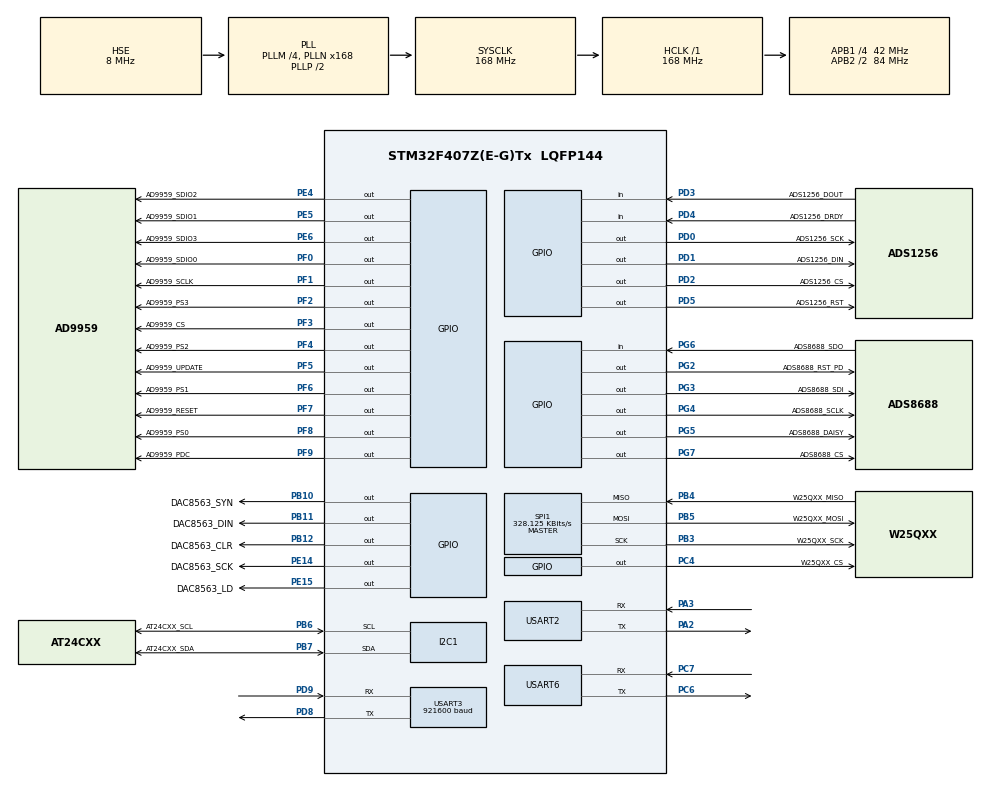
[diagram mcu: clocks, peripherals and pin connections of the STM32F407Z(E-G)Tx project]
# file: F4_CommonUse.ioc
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Dma.Request0=USART6_RX
Dma.USART6_RX.0.Direction=DMA_PERIPH_TO_MEMORY
Dma.USART6_RX.0.FIFOMode=DMA_FIFOMODE_DISABLE
Dma.USART6_RX.0.Instance=DMA2_Stream1
Dma.USART6_RX.0.MemDataAlignment=DMA_MDATAALIGN_BYTE
Dma.USART6_RX.0.MemInc=DMA_MINC_ENABLE
Dma.USART6_RX.0.Mode=DMA_CIRCULAR
Dma.USART6_RX.0.PeriphDataAlignment=DMA_PDATAALIGN_BYTE
Dma.USART6_RX.0.PeriphInc=DMA_PINC_DISABLE
Dma.USART6_RX.0.Priority=DMA_PRIORITY_LOW
Mcu.Family=STM32F4
Mcu.Name=STM32F407Z(E-G)Tx
Mcu.Package=LQFP144
NVIC.DMA2_Stream1_IRQn=true\:0\:0\:false\:false\:true\:false\:true\:true
NVIC.PriorityGroup=NVIC_PRIORITYGROUP_4
NVIC.USART2_IRQn=true\:1\:0\:true\:false\:false\:true\:true\:true
NVIC.USART6_IRQn=true\:0\:0\:false\:false\:false\:true\:true\:true
PA13.Mode=Serial_Wire
PA13.Signal=SYS_JTMS-SWDIO
PA14.Mode=Serial_Wire
PA14.Signal=SYS_JTCK-SWCLK
PA2.Mode=Asynchronous
PA2.Signal=USART2_TX
PA3.Mode=Asynchronous
PA3.Signal=USART2_RX
PB10.GPIO_Label=DAC8563_SYN
PB10.GPIO_Speed=GPIO_SPEED_FREQ_VERY_HIGH
PB10.Signal=GPIO_Output
PB11.GPIO_Label=DAC8563_DIN
PB11.GPIO_Speed=GPIO_SPEED_FREQ_VERY_HIGH
PB11.Signal=GPIO_Output
PB12.GPIO_Label=DAC8563_CLR
PB12.GPIO_Speed=GPIO_SPEED_FREQ_VERY_HIGH
PB12.Signal=GPIO_Output
PB3.GPIO_Label=W25QXX_SCK
PB3.Mode=Full_Duplex_Master
PB3.Signal=SPI1_SCK
PB4.GPIO_Label=W25QXX_MISO
PB4.Mode=Full_Duplex_Master
PB4.Signal=SPI1_MISO
PB5.GPIO_Label=W25QXX_MOSI
PB5.Mode=Full_Duplex_Master
PB5.Signal=SPI1_MOSI
PB6.GPIO_Label=AT24CXX_SCL
PB6.Mode=I2C
PB6.Signal=I2C1_SCL
PB7.GPIO_Label=AT24CXX_SDA
PB7.Mode=I2C
PB7.Signal=I2C1_SDA
PC14-OSC32_IN.Mode=LSE-External-Oscillator
PC14-OSC32_IN.Signal=RCC_OSC32_IN
PC15-OSC32_OUT.Mode=LSE-External-Oscillator
PC15-OSC32_OUT.Signal=RCC_OSC32_OUT
PC4.GPIO_Label=W25QXX_CS
PC4.GPIO_PuPd=GPIO_PULLUP
PC4.GPIO_Speed=GPIO_SPEED_FREQ_VERY_HIGH
PC4.PinState=GPIO_PIN_SET
PC4.Signal=GPIO_Output
PC6.Mode=Asynchronous
PC6.Signal=USART6_TX
PC7.Mode=Asynchronous
PC7.Signal=USART6_RX
PD0.GPIO_Label=ADS1256_SCK
PD0.GPIO_Speed=GPIO_SPEED_FREQ_VERY_HIGH
PD0.Signal=GPIO_Output
PD1.GPIO_Label=ADS1256_DIN
PD1.GPIO_Speed=GPIO_SPEED_FREQ_VERY_HIGH
PD1.Signal=GPIO_Output
PD2.GPIO_Label=ADS1256_CS
PD2.GPIO_Speed=GPIO_SPEED_FREQ_VERY_HIGH
PD2.Signal=GPIO_Output
PD3.GPIO_Label=ADS1256_DOUT
PD3.Signal=GPIO_Input
PD4.GPIO_Label=ADS1256_DRDY
PD4.GPIO_PuPd=GPIO_PULLDOWN
PD4.Signal=GPIO_Input
PD5.GPIO_Label=ADS1256_RST
PD5.GPIO_Speed=GPIO_SPEED_FREQ_VERY_HIGH
PD5.Signal=GPIO_Output
PD8.Mode=Asynchronous
PD8.Signal=USART3_TX
PD9.Mode=Asynchronous
PD9.Signal=USART3_RX
PE14.GPIO_Label=DAC8563_SCK
PE14.GPIO_Speed=GPIO_SPEED_FREQ_VERY_HIGH
PE14.Signal=GPIO_Output
PE15.GPIO_Label=DAC8563_LD
PE15.GPIO_Speed=GPIO_SPEED_FREQ_VERY_HIGH
PE15.Signal=GPIO_Output
PE4.GPIO_Label=AD9959_SDIO2
PE4.GPIO_Speed=GPIO_SPEED_FREQ_HIGH
PE4.Signal=GPIO_Output
PE5.GPIO_Label=AD9959_SDIO1
PE5.GPIO_Speed=GPIO_SPEED_FREQ_HIGH
PE5.Signal=GPIO_Output
PE6.GPIO_Label=AD9959_SDIO3
PE6.GPIO_Speed=GPIO_SPEED_FREQ_HIGH
PE6.Signal=GPIO_Output
PF0.GPIO_Label=AD9959_SDIO0
PF0.GPIO_Speed=GPIO_SPEED_FREQ_HIGH
PF0.Signal=GPIO_Output
PF1.GPIO_Label=AD9959_SCLK
PF1.GPIO_Speed=GPIO_SPEED_FREQ_HIGH
PF1.Signal=GPIO_Output
PF2.GPIO_Label=AD9959_PS3
PF2.GPIO_Speed=GPIO_SPEED_FREQ_HIGH
PF2.Signal=GPIO_Output
PF3.GPIO_Label=AD9959_CS
PF3.GPIO_Speed=GPIO_SPEED_FREQ_HIGH
PF3.Signal=GPIO_Output
PF4.GPIO_Label=AD9959_PS2
PF4.GPIO_Speed=GPIO_SPEED_FREQ_HIGH
PF4.Signal=GPIO_Output
PF5.GPIO_Label=AD9959_UPDATE
PF5.GPIO_Speed=GPIO_SPEED_FREQ_HIGH
PF5.Signal=GPIO_Output
PF6.GPIO_Label=AD9959_PS1
PF6.GPIO_Speed=GPIO_SPEED_FREQ_HIGH
PF6.Signal=GPIO_Output
PF7.GPIO_Label=AD9959_RESET
PF7.GPIO_Speed=GPIO_SPEED_FREQ_HIGH
PF7.Signal=GPIO_Output
PF8.GPIO_Label=AD9959_PS0
PF8.GPIO_Speed=GPIO_SPEED_FREQ_HIGH
PF8.Signal=GPIO_Output
PF9.GPIO_Label=AD9959_PDC
PF9.GPIO_Speed=GPIO_SPEED_FREQ_HIGH
PF9.Signal=GPIO_Output
PG2.GPIO_Label=ADS8688_RST_PD
PG2.GPIO_Speed=GPIO_SPEED_FREQ_HIGH
PG2.Signal=GPIO_Output
PG3.GPIO_Label=ADS8688_SDI
PG3.GPIO_Speed=GPIO_SPEED_FREQ_HIGH
PG3.Signal=GPIO_Output
PG4.GPIO_Label=ADS8688_SCLK
PG4.GPIO_Speed=GPIO_SPEED_FREQ_HIGH
PG4.Signal=GPIO_Output
PG5.GPIO_Label=ADS8688_DAISY
PG5.GPIO_Speed=GPIO_SPEED_FREQ_HIGH
PG5.Signal=GPIO_Output
PG6.GPIO_Label=ADS8688_SDO
PG6.Signal=GPIO_Input
PG7.GPIO_Label=ADS8688_CS
PG7.GPIO_Speed=GPIO_SPEED_FREQ_HIGH
PG7.Signal=GPIO_Output
PH0-OSC_IN.Mode=HSE-External-Oscillator
PH0-OSC_IN.Signal=RCC_OSC_IN
PH1-OSC_OUT.Mode=HSE-External-Oscillator
PH1-OSC_OUT.Signal=RCC_OSC_OUT
ProjectManager.HeapSize=0x200
ProjectManager.StackSize=0x800
ProjectManager.TargetToolchain=STM32CubeIDE
RCC.48MHZClocksFreq_Value=84000000
RCC.AHBFreq_Value=168000000
RCC.APB1CLKDivider=RCC_HCLK_DIV4
RCC.APB1Freq_Value=42000000
RCC.APB1TimFreq_Value=84000000
RCC.APB2CLKDivider=RCC_HCLK_DIV2
RCC.APB2Freq_Value=84000000
RCC.APB2TimFreq_Value=168000000
RCC.CortexFreq_Value=168000000
RCC.HCLKFreq_Value=168000000
RCC.HSE_VALUE=8000000
RCC.HSI_VALUE=16000000
RCC.PLLM=4
RCC.PLLN=168
RCC.PLLSourceVirtual=RCC_PLLSOURCE_HSE
RCC.SYSCLKFreq_VALUE=168000000
RCC.SYSCLKSource=RCC_SYSCLKSOURCE_PLLCLK
RCC.VCOOutputFreq_Value=336000000
SPI1.BaudRatePrescaler=SPI_BAUDRATEPRESCALER_256
SPI1.CLKPhase=SPI_PHASE_2EDGE
SPI1.CLKPolarity=SPI_POLARITY_HIGH
SPI1.CalculateBaudRate=328.125 KBits/s
SPI1.Direction=SPI_DIRECTION_2LINES
SPI1.Mode=SPI_MODE_MASTER
SPI1.VirtualType=VM_MASTER
STMicroelectronics.X-CUBE-ALGOBUILD.1.3.0.LibraryCcDSPOoLibraryJjDSPOoLibrary=true
USART2.VirtualMode=VM_ASYNC
USART3.BaudRate=921600
USART3.VirtualMode=VM_ASYNC
USART6.VirtualMode=VM_ASYNC
VP_STMicroelectronics.X-CUBE-ALGOBUILD_VS_DSPOoLibraryJjLibrary_1.3.0_1.3.0.Mode=DSPOoLibraryJjLibrary
VP_TIM6_VS_ClockSourceINT.Mode=Enable_Timer
VP_TIM6_VS_OPM.Mode=OPM_bit
board=custom

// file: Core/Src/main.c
/* USER CODE BEGIN Header */
/**
  ******************************************************************************
  * @file           : main.c
  * @brief          : Main program body
  ******************************************************************************
  * @attention
  *
  * Copyright (c) 2022 STMicroelectronics.
  * All rights reserved.
  *
  * This software is licensed under terms that can be found in the LICENSE file
  * in the root directory of this software component.
  * If no LICENSE file comes with this software, it is provided AS-IS.
  *
  ******************************************************************************
  */
/* USER CODE END Header */
#include "main.h"
#include "dma.h"
#include "i2c.h"
#include "spi.h"
#include "tim.h"
#include "usart.h"
#include "gpio.h"

/* USER CODE BEGIN Includes */
#include "base.h"
#include "arm_math.h"
#include "hmi_user_uart.h"
#include "cmd_process.h"
#include "ADS8688.h"
#include "AD9959.h"
#include "DAC8563.h"
#include "ADS1256.h"
#include "ESP8266.h"
#include "W25QXX.h"
#include "AT24CXX.h"
/* USER CODE END Includes */

void SystemClock_Config(void);

int main(void)
{
  /* USER CODE BEGIN 1 */
//  uint8_t writeData[20] = "Yogurt";
//  uint8_t readData[20] = "0";
  /* USER CODE END 1 */

  /* MCU Configuration--------------------------------------------------------*/

  /* Reset of all peripherals, Initializes the Flash interface and the Systick. */
  HAL_Init();

  /* USER CODE BEGIN Init */
  delay_init(168);
  /* USER CODE END Init */

  /* Configure the system clock */
  SystemClock_Config();

  /* Initialize all configured peripherals */
  MX_GPIO_Init();
  MX_USART2_UART_Init();		//串口屏
  MX_DMA_Init();
  MX_USART6_UART_Init();
  MX_USART3_UART_Init();
  MX_TIM6_Init();
  MX_I2C1_Init();
  MX_SPI1_Init();
  /* USER CODE BEGIN 2 */
  TFT_Init();
//  ADS1256_Init();
//  ADS1256_CfgADC(PGA_1, DATARATE_30K);	//增益1:1, 数据30kHz

  /* W25QXX CODE BEGIN */
//  W25QXX_Erase_Sector(0);
//  W25QXX_Write_NoCheck(writeData,0x00,sizeof(writeData));
//  for(;;){
//	  HAL_Delay(500);
//	  W25QXX_Read(readData,0x00,sizeof(writeData));
//	  HAL_Delay(100);
//	  print(&huart2,"%s\r\n",readData);
//
//  }
  /* W25QXX CODE END */

//  AT24CXX_Write(0x00,writeData,sizeof(writeData));
//  HAL_Delay(100);
//  for(;;){
//	  HAL_Delay(500);
//	  AT24CXX_Read(0x00,readData,sizeof(writeData));
//	  HAL_Delay(100);
//	  print(&huart2,"%s\r\n",readData);
//  }

  /* ESP8266 CODE BEGIN */
//  char buf[128];
//
//  init();

  //first
//  sendCmd("ATE0"    , "OK" , 100);  				//关闭回显
//  sendCmd("AT+CWMODE_DEF=3","OK",1500);			//设置ESP8266为AP模式
//
//  //设置模块的AP模式
//  sprintf(buf,"AT+CWSAP=\"%s\",\"%s\",%s,%s","ATK_ESP8266","12345678","10","4");
//  sendCmd(buf,"OK",2000);
//
//  /* 设置模块AP当前IP地址 */
//  sprintf(buf,"AT+CIPAP_CUR=\"%s\",\"%s\",\"%s\"", "192.168.0.233","192.168.5.1","255.255.255.0");
//  sendCmd(buf, "OK", 1500);
//
//  //创建多连接
//  sendCmd("AT+CIPMUX=1","OK",1000);
//
//  //创建模块TCP服务器
//  //创建TCP服务器之后，会自动启动TCP服务监听，当有TCP客户端连接时，会有CONNECT提示
//  sprintf(buf,"AT+CIPSERVER=%s,%s","1","1001");
//  sendCmd(buf,"OK",2000);

  //second
//  	while(sendCmd("AT", "OK", 100) == Timeout){
//  		quitTrans(); //退出透传
//  	}
//
//  	sendCmd("ATE0"    , "OK" , 100);  //关闭回显
//  	sendCmd("AT+CWMODE_DEF=1","OK",1500);			//设置ESP8266为STA模式
//  	//	sendCmd("AT+CWLAP", "OK" , 5000); //显示可加入的AP
//
//  	/* 加入wifi */
//  	sprintf(buf,"AT+CWJAP=\"%s\",\"%s\"","ATK_ESP8266","12345678");
//  	sendCmd(buf, "WIFI GOT IP", 15000); //加入AP
//  	send((char*)"", "OK"         , 2000); //加入AP
//
//  	/* 设置IP */
//  	sprintf(buf,"AT+CIPSTA=\"%s\"", "192.168.0.133");
//  	sendCmd(buf, "OK", 15000);
//
//  	/* 与PC机建立连接 */
//  	sprintf(buf,"AT+CIPSTART=\"%s\",\"%s\",%s", "TCP", "192.168.0.233", "1001");
//  //	sprintf(buf,"AT+CIPSTART=\"%s\",\"%s\",%s", "TCP", "192.168.43.66", "8087");
//  	sendCmd(buf, "OK", 15000);

  	/* 进入透传模式 */
//  	sendCmd("AT+CIPMODE=1", "OK", 200); //开启透传模式
//  	sendCmd("AT+CIPSEND"  , ">", 100); //进入透传

//  //发送消息
//  while(1){
//	  static int num=0;
//	  sprintf(buf,"%4d\r\n",num++);
//
//	  sendMessage(buf,"0","6");
//	  sendMessage(buf,"1","6");
//	  sendMessage(buf,"2","6");
//  }
  /* ESP8266 CODE END */

  /* USER CODE END 2 */

  /* Infinite loop */
  while (1)
  {

  }
}

void SystemClock_Config(void)
{
  RCC_OscInitTypeDef RCC_OscInitStruct = {0};
  RCC_ClkInitTypeDef RCC_ClkInitStruct = {0};

  /** Configure the main internal regulator output voltage
  */
  __HAL_RCC_PWR_CLK_ENABLE();
  __HAL_PWR_VOLTAGESCALING_CONFIG(PWR_REGULATOR_VOLTAGE_SCALE1);

  /** Initializes the RCC Oscillators according to the specified parameters
  * in the RCC_OscInitTypeDef structure.
  */
  RCC_OscInitStruct.OscillatorType = RCC_OSCILLATORTYPE_HSE;
  RCC_OscInitStruct.HSEState = RCC_HSE_ON;
  RCC_OscInitStruct.PLL.PLLState = RCC_PLL_ON;
  RCC_OscInitStruct.PLL.PLLSource = RCC_PLLSOURCE_HSE;
  RCC_OscInitStruct.PLL.PLLM = 4;
  RCC_OscInitStruct.PLL.PLLN = 168;
  RCC_OscInitStruct.PLL.PLLP = RCC_PLLP_DIV2;
  RCC_OscInitStruct.PLL.PLLQ = 4;
  if (HAL_RCC_OscConfig(&RCC_OscInitStruct) != HAL_OK)
  {
    Error_Handler();
  }

  /** Initializes the CPU, AHB and APB buses clocks
  */
  RCC_ClkInitStruct.ClockType = RCC_CLOCKTYPE_HCLK|RCC_CLOCKTYPE_SYSCLK
                              |RCC_CLOCKTYPE_PCLK1|RCC_CLOCKTYPE_PCLK2;
  RCC_ClkInitStruct.SYSCLKSource = RCC_SYSCLKSOURCE_PLLCLK;
  RCC_ClkInitStruct.AHBCLKDivider = RCC_SYSCLK_DIV1;
  RCC_ClkInitStruct.APB1CLKDivider = RCC_HCLK_DIV4;
  RCC_ClkInitStruct.APB2CLKDivider = RCC_HCLK_DIV2;

  if (HAL_RCC_ClockConfig(&RCC_ClkInitStruct, FLASH_LATENCY_5) != HAL_OK)
  {
    Error_Handler();
  }
}

void Error_Handler(void)
{
  __disable_irq();
  while (1)
  {
  }
}
